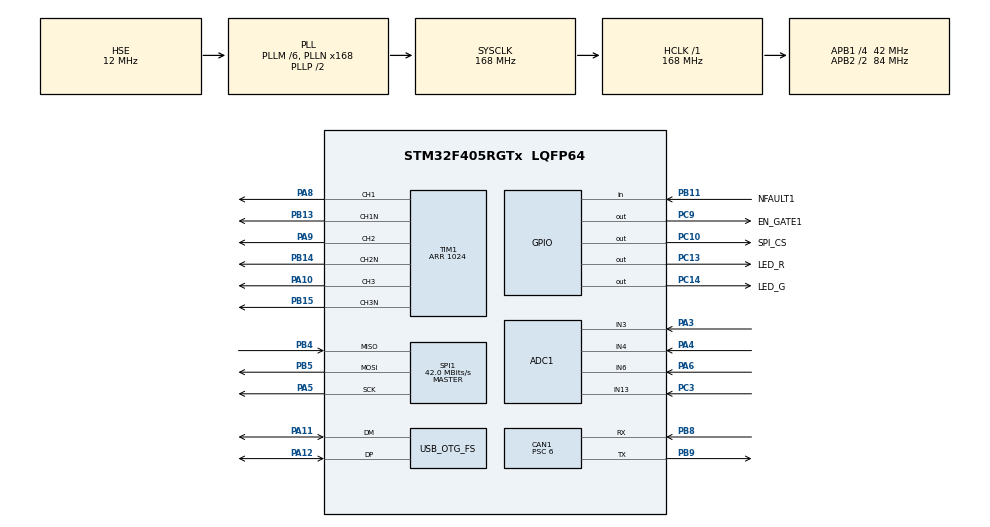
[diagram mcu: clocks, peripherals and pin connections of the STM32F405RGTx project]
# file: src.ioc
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ADC1.Channel-0\#ChannelRegularConversion=ADC_CHANNEL_13
ADC1.Channel-1\#ChannelInjectedConversion=ADC_CHANNEL_13
ADC1.Channel-2\#ChannelInjectedConversion=ADC_CHANNEL_3
ADC1.Channel-3\#ChannelInjectedConversion=ADC_CHANNEL_4
ADC1.Channel-4\#ChannelInjectedConversion=ADC_CHANNEL_6
ADC1.ExternalTrigInjecConv=ADC_EXTERNALTRIGINJECCONV_T1_CC4
ADC1.ExternalTrigInjecConvEdge=ADC_EXTERNALTRIGINJECCONVEDGE_FALLING
ADC1.InjNumberOfConversion=4
ADC1.InjectedOffset-1\#ChannelInjectedConversion=0
ADC1.InjectedOffset-2\#ChannelInjectedConversion=0
ADC1.InjectedOffset-3\#ChannelInjectedConversion=0
ADC1.InjectedOffset-4\#ChannelInjectedConversion=0
ADC1.InjectedRank-1\#ChannelInjectedConversion=1
ADC1.InjectedRank-2\#ChannelInjectedConversion=2
ADC1.InjectedRank-3\#ChannelInjectedConversion=3
ADC1.InjectedRank-4\#ChannelInjectedConversion=4
ADC1.NbrOfConversionFlag=1
ADC1.Rank-0\#ChannelRegularConversion=1
ADC1.SamplingTime-0\#ChannelRegularConversion=ADC_SAMPLETIME_3CYCLES
ADC1.SamplingTime-1\#ChannelInjectedConversion=ADC_SAMPLETIME_28CYCLES
ADC1.SamplingTime-2\#ChannelInjectedConversion=ADC_SAMPLETIME_28CYCLES
ADC1.SamplingTime-3\#ChannelInjectedConversion=ADC_SAMPLETIME_28CYCLES
ADC1.SamplingTime-4\#ChannelInjectedConversion=ADC_SAMPLETIME_28CYCLES
ADC1.ScanConvMode=ENABLE
ADC1.master=1
CAN1.BS1=CAN_BS1_8TQ
CAN1.BS2=CAN_BS2_5TQ
CAN1.CalculateBaudRate=500000
CAN1.CalculateTimeBit=2000
CAN1.CalculateTimeQuantum=142.85714285714286
CAN1.NART=ENABLE
CAN1.Prescaler=6
CAN1.SJW=CAN_SJW_2TQ
Dma.Request0=SPI1_TX
Dma.Request1=SPI1_RX
Dma.SPI1_RX.1.Direction=DMA_PERIPH_TO_MEMORY
Dma.SPI1_RX.1.FIFOMode=DMA_FIFOMODE_DISABLE
Dma.SPI1_RX.1.Instance=DMA2_Stream0
Dma.SPI1_RX.1.MemDataAlignment=DMA_MDATAALIGN_BYTE
Dma.SPI1_RX.1.MemInc=DMA_MINC_ENABLE
Dma.SPI1_RX.1.Mode=DMA_NORMAL
Dma.SPI1_RX.1.PeriphDataAlignment=DMA_PDATAALIGN_BYTE
Dma.SPI1_RX.1.PeriphInc=DMA_PINC_DISABLE
Dma.SPI1_RX.1.Priority=DMA_PRIORITY_HIGH
Dma.SPI1_TX.0.Direction=DMA_MEMORY_TO_PERIPH
Dma.SPI1_TX.0.FIFOMode=DMA_FIFOMODE_DISABLE
Dma.SPI1_TX.0.Instance=DMA2_Stream3
Dma.SPI1_TX.0.MemDataAlignment=DMA_MDATAALIGN_BYTE
Dma.SPI1_TX.0.MemInc=DMA_MINC_ENABLE
Dma.SPI1_TX.0.Mode=DMA_NORMAL
Dma.SPI1_TX.0.PeriphDataAlignment=DMA_PDATAALIGN_BYTE
Dma.SPI1_TX.0.PeriphInc=DMA_PINC_DISABLE
Dma.SPI1_TX.0.Priority=DMA_PRIORITY_HIGH
Mcu.Family=STM32F4
Mcu.Name=STM32F405RGTx
Mcu.Package=LQFP64
NVIC.ADC_IRQn=true\:0\:0\:false\:false\:true\:true\:true\:true
NVIC.CAN1_RX0_IRQn=true\:0\:0\:false\:false\:true\:true\:true\:true
NVIC.CAN1_RX1_IRQn=true\:0\:0\:false\:false\:true\:true\:true\:true
NVIC.DMA2_Stream0_IRQn=true\:0\:0\:false\:false\:true\:false\:true\:true
NVIC.DMA2_Stream3_IRQn=true\:0\:0\:false\:false\:true\:false\:true\:true
NVIC.OTG_FS_IRQn=true\:0\:0\:false\:false\:true\:false\:true\:true
NVIC.PriorityGroup=NVIC_PRIORITYGROUP_4
NVIC.SPI1_IRQn=true\:0\:0\:false\:false\:true\:true\:true\:true
PA10.Signal=S_TIM1_CH3
PA11.Mode=Device_Only
PA11.Signal=USB_OTG_FS_DM
PA12.Mode=Device_Only
PA12.Signal=USB_OTG_FS_DP
PA13.Mode=Serial_Wire
PA13.Signal=SYS_JTMS-SWDIO
PA14.Mode=Serial_Wire
PA14.Signal=SYS_JTCK-SWCLK
PA3.Signal=ADCx_IN3
PA4.Signal=ADCx_IN4
PA5.Mode=Full_Duplex_Master
PA5.Signal=SPI1_SCK
PA6.Signal=ADCx_IN6
PA8.Signal=S_TIM1_CH1
PA9.Signal=S_TIM1_CH2
PB11.GPIO_Label=NFAULT1
PB11.Signal=GPIO_Input
PB13.Mode=PWM Generation1 CH1 CH1N
PB13.Signal=TIM1_CH1N
PB14.Mode=PWM Generation2 CH2 CH2N
PB14.Signal=TIM1_CH2N
PB15.Mode=PWM Generation3 CH3 CH3N
PB15.Signal=TIM1_CH3N
PB4.Mode=Full_Duplex_Master
PB4.Signal=SPI1_MISO
PB5.Mode=Full_Duplex_Master
PB5.Signal=SPI1_MOSI
PB8.GPIO_PuPd=GPIO_PULLUP
PB8.Mode=CAN_Activate
PB8.Signal=CAN1_RX
PB9.Mode=CAN_Activate
PB9.Signal=CAN1_TX
PC10.GPIO_Label=SPI_CS
PC10.Signal=GPIO_Output
PC13-ANTI_TAMP.GPIO_Label=LED_R
PC13-ANTI_TAMP.Signal=GPIO_Output
PC14-OSC32_IN.GPIO_Label=LED_G
PC14-OSC32_IN.Signal=GPIO_Output
PC3.Signal=ADCx_IN13
PC9.GPIO_Label=EN_GATE1
PC9.Signal=GPIO_Output
PH0-OSC_IN.Mode=HSE-External-Oscillator
PH0-OSC_IN.Signal=RCC_OSC_IN
PH1-OSC_OUT.Mode=HSE-External-Oscillator
PH1-OSC_OUT.Signal=RCC_OSC_OUT
ProjectManager.HeapSize=0x200
ProjectManager.StackSize=0x400
ProjectManager.TargetToolchain=EWARM V8.50
RCC.48MHZClocksFreq_Value=48000000
RCC.AHBFreq_Value=168000000
RCC.APB1CLKDivider=RCC_HCLK_DIV4
RCC.APB1Freq_Value=42000000
RCC.APB1TimFreq_Value=84000000
RCC.APB2CLKDivider=RCC_HCLK_DIV2
RCC.APB2Freq_Value=84000000
RCC.APB2TimFreq_Value=168000000
RCC.CortexFreq_Value=168000000
RCC.HCLKFreq_Value=168000000
RCC.HSE_VALUE=12000000
RCC.HSI_VALUE=16000000
RCC.LSE_VALUE=32768
RCC.PLLM=6
RCC.PLLN=168
RCC.PLLQ=7
RCC.SYSCLKFreq_VALUE=168000000
RCC.SYSCLKSource=RCC_SYSCLKSOURCE_PLLCLK
RCC.VCOOutputFreq_Value=336000000
SH.ADCx_IN13.0=ADC1_IN13,IN13
SH.ADCx_IN3.0=ADC1_IN3,IN3
SH.ADCx_IN4.0=ADC1_IN4,IN4
SH.ADCx_IN6.0=ADC1_IN6,IN6
SH.S_TIM1_CH1.0=TIM1_CH1,PWM Generation1 CH1 CH1N
SH.S_TIM1_CH2.0=TIM1_CH2,PWM Generation2 CH2 CH2N
SH.S_TIM1_CH3.0=TIM1_CH3,PWM Generation3 CH3 CH3N
SPI1.CLKPhase=SPI_PHASE_2EDGE
SPI1.CalculateBaudRate=42.0 MBits/s
SPI1.Direction=SPI_DIRECTION_2LINES
SPI1.Mode=SPI_MODE_MASTER
SPI1.VirtualType=VM_MASTER
TIM1.AutomaticOutput=TIM_AUTOMATICOUTPUT_ENABLE
TIM1.Channel-PWM\ Generation1\ CH1\ CH1N=TIM_CHANNEL_1
TIM1.Channel-PWM\ Generation2\ CH2\ CH2N=TIM_CHANNEL_2
TIM1.Channel-PWM\ Generation3\ CH3\ CH3N=TIM_CHANNEL_3
TIM1.Channel-PWM\ Generation4\ No\ Output=TIM_CHANNEL_4
TIM1.CounterMode=TIM_COUNTERMODE_CENTERALIGNED1
TIM1.DeadTime=25
TIM1.OCFastMode_PWM-PWM\ Generation1\ CH1\ CH1N=TIM_OCFAST_ENABLE
TIM1.OCFastMode_PWM-PWM\ Generation2\ CH2\ CH2N=TIM_OCFAST_ENABLE
TIM1.OCFastMode_PWM-PWM\ Generation3\ CH3\ CH3N=TIM_OCFAST_ENABLE
TIM1.OCFastMode_PWM-PWM\ Generation4\ No\ Output=TIM_OCFAST_ENABLE
TIM1.OffStateIDLEMode=TIM_OSSI_ENABLE
TIM1.OffStateRunMode=TIM_OSSR_ENABLE
TIM1.Period=1024
TIM1.TIM_MasterOutputTrigger=TIM_TRGO_UPDATE
USB_DEVICE.CLASS_NAME_FS=CDC
USB_DEVICE.VirtualMode-CDC_FS=Cdc
USB_DEVICE.VirtualModeFS=Cdc_FS
USB_OTG_FS.VirtualMode=Device_Only
VP_TIM1_VS_ClockSourceINT.Mode=Internal
VP_TIM1_VS_no_output4.Mode=PWM Generation4 No Output
VP_USB_DEVICE_VS_USB_DEVICE_CDC_FS.Mode=CDC_FS
board=custom

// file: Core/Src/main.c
/* USER CODE BEGIN Header */
/**
  ******************************************************************************
  * @file           : main.c
  * @brief          : Main program body
  ******************************************************************************
  * @attention
  *
  * Copyright (c) 2026 STMicroelectronics.
  * All rights reserved.
  *
  * This software is licensed under terms that can be found in the LICENSE file
  * in the root directory of this software component.
  * If no LICENSE file comes with this software, it is provided AS-IS.
  *
  ******************************************************************************
  */
/* USER CODE END Header */
#include "main.h"
#include "usb_device.h"

/* USER CODE BEGIN Includes */
#include "device_config.h"
#include "stm32f405_link.h"
#include "motor.h"
#include "AS5047P.h"
#include "FOC_utils.h"
#include "self_commissioning.h"
#include "storage.h"
#include "sf_motion_usb_com.h"
#include "sf_motion_com.h"
#include "string.h"
/* USER CODE END Includes */

/* USER CODE BEGIN PD */

#define usb_print(fmt, ...)                                                 \
  do {                                                                      \
    snprintf(usb_send_buff, sizeof(usb_send_buff), fmt, ##__VA_ARGS__);     \
    CDC_Transmit_FS((uint8_t *)(usb_send_buff), sizeof(usb_send_buff) - 1); \
  } while (0)

/* USER CODE END PD */

/* USER CODE BEGIN PM */
extern uint8_t CDC_Transmit_FS(uint8_t* Buf, uint16_t Len);
/* USER CODE END PM */

ADC_HandleTypeDef hadc1;

CAN_HandleTypeDef hcan1;

SPI_HandleTypeDef hspi1;
DMA_HandleTypeDef hdma_spi1_tx;
DMA_HandleTypeDef hdma_spi1_rx;

TIM_HandleTypeDef htim1;

/* USER CODE BEGIN PV */

AS5047P_t hencd1;
uint32_t adc_buff[4];
foc_t hfoc1;
self_commissioning_t hsc1;
storage_t hstorage1;

sfm_usb_com_t hsfm_usb_com;
sfm_com_t husb_com;
sfm_com_t hcan_com;

char usb_send_buff[64];
uint8_t can_send_buff[64];
uint8_t can_recv_buff[64];

/* USER CODE END PV */

void SystemClock_Config(void);
static void MX_GPIO_Init(void);
static void MX_DMA_Init(void);
static void MX_TIM1_Init(void);
static void MX_ADC1_Init(void);
static void MX_SPI1_Init(void);
static void MX_CAN1_Init(void);

/* USER CODE BEGIN 0 */

/**************************************************************************** */
// implementation

void motor1_inverter_enable(void) {
  EN_GATE1_GPIO_Port->BSRR = EN_GATE1_Pin;
  link_enable_pwm(&htim1);
  link_enable_adc(&hadc1);
}

void motor1_inverter_disable(void) {
  EN_GATE1_GPIO_Port->BSRR = EN_GATE1_Pin<<16;
  link_disable_pwm(&htim1);
  link_disable_adc(&hadc1);
}

uint32_t motor1_get_pwm_res(void) {
  return link_get_max_pwm(&htim1);
}

float motor1_as5047p_get_mech_deg(void) {
  return AS5047P_get_degree(&hencd1);
}

float motor1_as5047p_get_continuous_mech_deg(void) {
  return AS5047P_get_continuous_degree(&hencd1);
}

float motor1_as5047p_get_rpm(void) {
  return AS5047P_get_rpm(&hencd1);
}

int motor1_as5047p_spi_transmit(uint8_t *tx, uint8_t *rx, uint16_t len) {
  if (HAL_SPI_TransmitReceive_DMA(&hspi1, tx, rx, len) == HAL_OK) return 0;
  return -1;
}

void motor1_as5047p_spi_cs(_Bool cs_state) {
  if (cs_state) SPI_CS_GPIO_Port->BSRR = SPI_CS_Pin;
  else SPI_CS_GPIO_Port->BSRR = SPI_CS_Pin<<16;
}

int write_flash(void *data, uint32_t len) {
  return link_write_flash(data, len);
}

int read_flash(void *data, uint32_t len) {
  memcpy(data, (void*)FLASH_SECTOR_ADDR, len);
  return 0;
}

int usb_send_data(uint8_t *data, uint16_t len) {
  if (CDC_Transmit_FS(data, len) != USBD_OK) return -1;
  return 0;
}

int sfm_com_usb_send_data(uint8_t *data, uint16_t len) {
  if (sfm_usb_com_start_send_data(&hsfm_usb_com, data, len) == 0) return 0;
  return -1;
}

int sfm_com_usb_recv_data(uint8_t *data, uint16_t len) {
  (void)data;
  (void)len;
  return 0;
}

int can_recv_data(uint8_t *data, uint16_t len) {
  (void)data;
  (void)len;
  return 0;
}

int can_send_data(uint8_t *data, uint16_t len) {
  uint32_t can_std_id = (data[0] << 8) | data[1];
  return link_can_send_data(can_std_id, data + 2, len);
}

/**************************************************************************** */

static void init_motor(void) {
  // motor pwm
  motor_init_pwm(&hfoc1.motor, &TIM1->CCR1, &TIM1->CCR2, &TIM1->CCR3);
  // current sense
  motor_init_adc_current_sense(&hfoc1.motor, &adc_buff[0], &adc_buff[1], &adc_buff[2]);
  // power voltage sense
  motor_init_adc_power_voltage_sense(&hfoc1.motor, &adc_buff[3]);
  motor_init_lpf_power_voltage_sense(&hfoc1.motor, hstorage1.memory.voltage_sens.filter_fc, BLDC_PWM_FREQ);
  // current sense amplifier calibration enable (for internal CSA only)
  CSA_CAL1_GPIO_Port->BSRR = CSA_CAL1_Pin << 16;
}

static void init_encoder(void) {
  AS5047P_spi_config(&hencd1, motor1_as5047p_spi_transmit, motor1_as5047p_spi_cs);
  AS5047P_init(&hencd1,
              hstorage1.memory.encoder_config.is_dir_inverted? SENSOR_DIR_REVERSE : SENSOR_DIR_NORMAL,
              hstorage1.memory.encoder_config.scale);
  AS5047P_set_pll_filter(&hencd1,
                        hstorage1.memory.encoder_config.pll_filt_bandwidth,
                        hstorage1.memory.encoder_config.pll_filt_damping_ratio,
                        FOC_TS);
}

static void init_foc(void) {
#if USB_TO_CAN
  link_can_init(USB_TO_CAN_DEVICE_ID);
  sfm_usb_com_init(&hsfm_usb_com, usb_send_data);
  sfm_com_init(&husb_com, sfm_com_usb_recv_data, sfm_com_usb_send_data, HAL_GetTick, &hfoc1, &hstorage1, &hsc1);
  sfm_com_init(&hcan_com, can_recv_data, can_send_data, HAL_GetTick, &hfoc1, &hstorage1, &hsc1);
#else
  storage_init(&hstorage1, write_flash, read_flash);
  storage_read_config(&hstorage1);
  storage_copy_to_local(&hstorage1, &hfoc1);

  init_trig_lut();
  link_set_pwm_freq(&htim1, BLDC_PWM_FREQ);
  init_motor();
  init_encoder();
  sc_init(&hsc1, &hfoc1);

  foc_inverter_init(&hfoc1, motor1_inverter_enable, motor1_inverter_disable, motor1_get_pwm_res);
  foc_feedback_sensor_init(&hfoc1,
                          motor1_as5047p_get_mech_deg,
                          motor1_as5047p_get_continuous_mech_deg,
                          motor1_as5047p_get_rpm,
                          hstorage1.memory.encoder_config.error_comp_deg);

  link_can_init(hfoc1.motor.device_id);
  sfm_usb_com_init(&hsfm_usb_com, usb_send_data);
  sfm_com_init(&husb_com,
              sfm_com_usb_recv_data,
              sfm_com_usb_send_data,
              HAL_GetTick,
              link_system_reset,
              &hfoc1, &hstorage1, &hsc1);
  sfm_com_init(&hcan_com,
              can_recv_data,
              can_send_data,
              HAL_GetTick,
              link_system_reset,
              &hfoc1, &hstorage1, &hsc1);

  // Id PI parameter
  pid_reset(&hfoc1.id_ctrl);
  pid_set_ts(&hfoc1.id_ctrl, FOC_TS);
  // Id PI parameter
  pid_reset(&hfoc1.iq_ctrl);
  pid_set_ts(&hfoc1.iq_ctrl, FOC_TS);
  // Speed PID parameter
  pid_reset(&hfoc1.speed_ctrl);
  pid_set_ts(&hfoc1.speed_ctrl, SPEED_TS);
  // Position PID parameter
  pid_reset(&hfoc1.pos_ctrl);
  pid_set_ts(&hfoc1.pos_ctrl, POSITION_TS);
  pid_set_max_d(&hfoc1.pos_ctrl, 100.0f);
  // field weakening
  pid_reset(&hfoc1.fw_ctrl);
  pid_set_ts(&hfoc1.fw_ctrl, FOC_TS);

  // foc_set_mode(&hfoc1, FOC_MODE_SENSORED);
  foc_sensorless_init(&hfoc1, BLDC_PWM_FREQ);

  HAL_Delay(50);
  foc_enable(&hfoc1);
#endif
}

static void indicator_update(void) {
  static uint32_t heartbeat_tick = 0;
  if (HAL_GetTick() - heartbeat_tick >= 500) {
    heartbeat_tick = HAL_GetTick();
    HAL_GPIO_TogglePin(LED_G_GPIO_Port, LED_G_Pin);
  }
  if (HAL_GPIO_ReadPin(NFAULT1_GPIO_Port, NFAULT1_Pin)) {
    LED_R_GPIO_Port->BSRR = LED_R_Pin<<16;
  }
  else {
    LED_R_GPIO_Port->BSRR = LED_R_Pin;
  }
}

static void self_commissioning_update(void) {
  if (sc_is_measure_done(&hsc1)) {
    switch(sc_get_seq(&hsc1)) {
      case SC_SEQUENCE_START_MEASURE_RS:
        foc_set_motor_Rs(&hfoc1, sc_get_Rs(&hsc1));
        break;
      case SC_SEQUENCE_START_MEASURE_LD:
        foc_set_motor_Ld(&hfoc1, sc_get_Ld(&hsc1));
        break;
      case SC_SEQUENCE_START_MEASURE_LQ:
        foc_set_motor_Lq(&hfoc1, sc_get_Lq(&hsc1));
        break;
      case SC_SEQUENCE_START_CALIBRATE_ABS_ENCODER:
        break;
      case SC_SEQUENCE_START_CALC_POLE_PAIRS:
        break;
      default:
        break;
    }
    sfm_com_send_event(&husb_com, SFM_EVENT_SELFCOM_DONE);
    sfm_com_send_event(&hcan_com, SFM_EVENT_SELFCOM_DONE);
  }
}

void usb_to_can_update(void) {
  if (husb_com.incomming_data_flag) {
    husb_com.incomming_data_flag = 0;
    hcan_com.send_data(husb_com.data_rx, husb_com.data_rx_len);
  }
  if (hcan_com.incomming_data_flag) {
    hcan_com.incomming_data_flag = 0;
    husb_com.send_data(hcan_com.data_rx, hcan_com.data_rx_len);
  }
}

/**************************************************************************** */

void HAL_SPI_TxRxCpltCallback(SPI_HandleTypeDef *hspi) {
	if (hspi->Instance == SPI1) {
    AS5047P_set_spi_transfer_done(&hencd1);
	}
}

void HAL_ADCEx_InjectedConvCpltCallback(ADC_HandleTypeDef* hadc) {
	if (hadc->Instance == ADC1) {
    adc_buff[0] = ADC1->JDR1; // current sense A
    adc_buff[1] = ADC1->JDR2; // current sense B
    adc_buff[2] = ADC1->JDR3; // current sense C
    adc_buff[3] = ADC1->JDR4; // power voltage sense
    motor_calculate_power_voltage(&hfoc1.motor);
    motor_get_power_voltage(&hfoc1.motor, &hfoc1.v_bus);
    AS5047P_pll_filter_update(&hencd1);
    sc_update(&hsc1, FOC_TS);
    foc_update(&hfoc1, FOC_TS);
  }
}

// CAN RX FIFO 0 Callback
void HAL_CAN_RxFifo0MsgPendingCallback(CAN_HandleTypeDef *hcan){
  uint32_t id;
  if (link_can_recv_data(&id, hcan_com.data_rx, &hcan_com.data_rx_len) == 0) {
    hcan_com.incomming_data_flag = 1;
  }
}

/**************************************************************************** */

/* USER CODE END 0 */

int main(void)
{

  /* MCU Configuration--------------------------------------------------------*/

  /* Reset of all peripherals, Initializes the Flash interface and the Systick. */
  HAL_Init();

  /* Configure the system clock */
  SystemClock_Config();

  /* Initialize all configured peripherals */
  MX_GPIO_Init();
  MX_DMA_Init();
  MX_USB_DEVICE_Init();
  MX_TIM1_Init();
  MX_ADC1_Init();
  MX_SPI1_Init();
  MX_CAN1_Init();
  /* USER CODE BEGIN 2 */

#if (__FPU_PRESENT == 1) && (__FPU_USED == 1)
  printf("FPU aktif!\n");
#else
  printf("FPU tidak aktif!\n");
#endif

  init_foc();

  /* USER CODE END 2 */

  /* Infinite loop */
  /* USER CODE BEGIN WHILE */
  while (1)
  {
    indicator_update();
#if USB_TO_CAN
    usb_to_can_update();
#else
    AS5047P_update(&hencd1);
    sfm_com_update(&husb_com);
    sfm_com_update(&hcan_com);
    self_commissioning_update();
#endif
    /* USER CODE END WHILE */

  }
}

void SystemClock_Config(void)
{
  RCC_OscInitTypeDef RCC_OscInitStruct = {0};
  RCC_ClkInitTypeDef RCC_ClkInitStruct = {0};

  /** Configure the main internal regulator output voltage
  */
  __HAL_RCC_PWR_CLK_ENABLE();
  __HAL_PWR_VOLTAGESCALING_CONFIG(PWR_REGULATOR_VOLTAGE_SCALE1);

  /** Initializes the RCC Oscillators according to the specified parameters
  * in the RCC_OscInitTypeDef structure.
  */
  RCC_OscInitStruct.OscillatorType = RCC_OSCILLATORTYPE_HSE;
  RCC_OscInitStruct.HSEState = RCC_HSE_ON;
  RCC_OscInitStruct.PLL.PLLState = RCC_PLL_ON;
  RCC_OscInitStruct.PLL.PLLSource = RCC_PLLSOURCE_HSE;
  RCC_OscInitStruct.PLL.PLLM = 6;
  RCC_OscInitStruct.PLL.PLLN = 168;
  RCC_OscInitStruct.PLL.PLLP = RCC_PLLP_DIV2;
  RCC_OscInitStruct.PLL.PLLQ = 7;
  if (HAL_RCC_OscConfig(&RCC_OscInitStruct) != HAL_OK)
  {
    Error_Handler();
  }

  /** Initializes the CPU, AHB and APB buses clocks
  */
  RCC_ClkInitStruct.ClockType = RCC_CLOCKTYPE_HCLK|RCC_CLOCKTYPE_SYSCLK
                              |RCC_CLOCKTYPE_PCLK1|RCC_CLOCKTYPE_PCLK2;
  RCC_ClkInitStruct.SYSCLKSource = RCC_SYSCLKSOURCE_PLLCLK;
  RCC_ClkInitStruct.AHBCLKDivider = RCC_SYSCLK_DIV1;
  RCC_ClkInitStruct.APB1CLKDivider = RCC_HCLK_DIV4;
  RCC_ClkInitStruct.APB2CLKDivider = RCC_HCLK_DIV2;

  if (HAL_RCC_ClockConfig(&RCC_ClkInitStruct, FLASH_LATENCY_5) != HAL_OK)
  {
    Error_Handler();
  }
}

static void MX_ADC1_Init(void)
{

  ADC_ChannelConfTypeDef sConfig = {0};
  ADC_InjectionConfTypeDef sConfigInjected = {0};

  /** Configure the global features of the ADC (Clock, Resolution, Data Alignment and number of conversion)
  */
  hadc1.Instance = ADC1;
  hadc1.Init.ClockPrescaler = ADC_CLOCK_SYNC_PCLK_DIV4;
  hadc1.Init.Resolution = ADC_RESOLUTION_12B;
  hadc1.Init.ScanConvMode = ENABLE;
  hadc1.Init.ContinuousConvMode = DISABLE;
  hadc1.Init.DiscontinuousConvMode = DISABLE;
  hadc1.Init.ExternalTrigConvEdge = ADC_EXTERNALTRIGCONVEDGE_NONE;
  hadc1.Init.ExternalTrigConv = ADC_SOFTWARE_START;
  hadc1.Init.DataAlign = ADC_DATAALIGN_RIGHT;
  hadc1.Init.NbrOfConversion = 1;
  hadc1.Init.DMAContinuousRequests = DISABLE;
  hadc1.Init.EOCSelection = ADC_EOC_SINGLE_CONV;
  if (HAL_ADC_Init(&hadc1) != HAL_OK)
  {
    Error_Handler();
  }

  /** Configure for the selected ADC regular channel its corresponding rank in the sequencer and its sample time.
  */
  sConfig.Channel = ADC_CHANNEL_13;
  sConfig.Rank = 1;
  sConfig.SamplingTime = ADC_SAMPLETIME_3CYCLES;
  if (HAL_ADC_ConfigChannel(&hadc1, &sConfig) != HAL_OK)
  {
    Error_Handler();
  }

  /** Configures for the selected ADC injected channel its corresponding rank in the sequencer and its sample time
  */
  sConfigInjected.InjectedChannel = ADC_CHANNEL_13;
  sConfigInjected.InjectedRank = 1;
  sConfigInjected.InjectedNbrOfConversion = 4;
  sConfigInjected.InjectedSamplingTime = ADC_SAMPLETIME_28CYCLES;
  sConfigInjected.ExternalTrigInjecConvEdge = ADC_EXTERNALTRIGINJECCONVEDGE_FALLING;
  sConfigInjected.ExternalTrigInjecConv = ADC_EXTERNALTRIGINJECCONV_T1_CC4;
  sConfigInjected.AutoInjectedConv = DISABLE;
  sConfigInjected.InjectedDiscontinuousConvMode = DISABLE;
  sConfigInjected.InjectedOffset = 0;
  if (HAL_ADCEx_InjectedConfigChannel(&hadc1, &sConfigInjected) != HAL_OK)
  {
    Error_Handler();
  }

  /** Configures for the selected ADC injected channel its corresponding rank in the sequencer and its sample time
  */
  sConfigInjected.InjectedChannel = ADC_CHANNEL_3;
  sConfigInjected.InjectedRank = 2;
  if (HAL_ADCEx_InjectedConfigChannel(&hadc1, &sConfigInjected) != HAL_OK)
  {
    Error_Handler();
  }

  /** Configures for the selected ADC injected channel its corresponding rank in the sequencer and its sample time
  */
  sConfigInjected.InjectedChannel = ADC_CHANNEL_4;
  sConfigInjected.InjectedRank = 3;
  if (HAL_ADCEx_InjectedConfigChannel(&hadc1, &sConfigInjected) != HAL_OK)
  {
    Error_Handler();
  }

  /** Configures for the selected ADC injected channel its corresponding rank in the sequencer and its sample time
  */
  sConfigInjected.InjectedChannel = ADC_CHANNEL_6;
  sConfigInjected.InjectedRank = 4;
  if (HAL_ADCEx_InjectedConfigChannel(&hadc1, &sConfigInjected) != HAL_OK)
  {
    Error_Handler();
  }

}

static void MX_CAN1_Init(void)
{

  hcan1.Instance = CAN1;
  hcan1.Init.Prescaler = 6;
  hcan1.Init.Mode = CAN_MODE_NORMAL;
  hcan1.Init.SyncJumpWidth = CAN_SJW_2TQ;
  hcan1.Init.TimeSeg1 = CAN_BS1_8TQ;
  hcan1.Init.TimeSeg2 = CAN_BS2_5TQ;
  hcan1.Init.TimeTriggeredMode = DISABLE;
  hcan1.Init.AutoBusOff = DISABLE;
  hcan1.Init.AutoWakeUp = DISABLE;
  hcan1.Init.AutoRetransmission = ENABLE;
  hcan1.Init.ReceiveFifoLocked = DISABLE;
  hcan1.Init.TransmitFifoPriority = DISABLE;
  if (HAL_CAN_Init(&hcan1) != HAL_OK)
  {
    Error_Handler();
  }

}

static void MX_SPI1_Init(void)
{

  /* SPI1 parameter configuration*/
  hspi1.Instance = SPI1;
  hspi1.Init.Mode = SPI_MODE_MASTER;
  hspi1.Init.Direction = SPI_DIRECTION_2LINES;
  hspi1.Init.DataSize = SPI_DATASIZE_8BIT;
  hspi1.Init.CLKPolarity = SPI_POLARITY_LOW;
  hspi1.Init.CLKPhase = SPI_PHASE_2EDGE;
  hspi1.Init.NSS = SPI_NSS_SOFT;
  hspi1.Init.BaudRatePrescaler = SPI_BAUDRATEPRESCALER_4;
  hspi1.Init.FirstBit = SPI_FIRSTBIT_MSB;
  hspi1.Init.TIMode = SPI_TIMODE_DISABLE;
  hspi1.Init.CRCCalculation = SPI_CRCCALCULATION_DISABLE;
  hspi1.Init.CRCPolynomial = 10;
  if (HAL_SPI_Init(&hspi1) != HAL_OK)
  {
    Error_Handler();
  }

}

static void MX_TIM1_Init(void)
{

  TIM_ClockConfigTypeDef sClockSourceConfig = {0};
  TIM_MasterConfigTypeDef sMasterConfig = {0};
  TIM_OC_InitTypeDef sConfigOC = {0};
  TIM_BreakDeadTimeConfigTypeDef sBreakDeadTimeConfig = {0};

  htim1.Instance = TIM1;
  htim1.Init.Prescaler = 0;
  htim1.Init.CounterMode = TIM_COUNTERMODE_CENTERALIGNED1;
  htim1.Init.Period = 1024;
  htim1.Init.ClockDivision = TIM_CLOCKDIVISION_DIV1;
  htim1.Init.RepetitionCounter = 0;
  htim1.Init.AutoReloadPreload = TIM_AUTORELOAD_PRELOAD_DISABLE;
  if (HAL_TIM_Base_Init(&htim1) != HAL_OK)
  {
    Error_Handler();
  }
  sClockSourceConfig.ClockSource = TIM_CLOCKSOURCE_INTERNAL;
  if (HAL_TIM_ConfigClockSource(&htim1, &sClockSourceConfig) != HAL_OK)
  {
    Error_Handler();
  }
  if (HAL_TIM_PWM_Init(&htim1) != HAL_OK)
  {
    Error_Handler();
  }
  sMasterConfig.MasterOutputTrigger = TIM_TRGO_UPDATE;
  sMasterConfig.MasterSlaveMode = TIM_MASTERSLAVEMODE_DISABLE;
  if (HAL_TIMEx_MasterConfigSynchronization(&htim1, &sMasterConfig) != HAL_OK)
  {
    Error_Handler();
  }
  sConfigOC.OCMode = TIM_OCMODE_PWM1;
  sConfigOC.Pulse = 0;
  sConfigOC.OCPolarity = TIM_OCPOLARITY_HIGH;
  sConfigOC.OCNPolarity = TIM_OCNPOLARITY_HIGH;
  sConfigOC.OCFastMode = TIM_OCFAST_ENABLE;
  sConfigOC.OCIdleState = TIM_OCIDLESTATE_RESET;
  sConfigOC.OCNIdleState = TIM_OCNIDLESTATE_RESET;
  if (HAL_TIM_PWM_ConfigChannel(&htim1, &sConfigOC, TIM_CHANNEL_1) != HAL_OK)
  {
    Error_Handler();
  }
  if (HAL_TIM_PWM_ConfigChannel(&htim1, &sConfigOC, TIM_CHANNEL_2) != HAL_OK)
  {
    Error_Handler();
  }
  if (HAL_TIM_PWM_ConfigChannel(&htim1, &sConfigOC, TIM_CHANNEL_3) != HAL_OK)
  {
    Error_Handler();
  }
  if (HAL_TIM_PWM_ConfigChannel(&htim1, &sConfigOC, TIM_CHANNEL_4) != HAL_OK)
  {
    Error_Handler();
  }
  sBreakDeadTimeConfig.OffStateRunMode = TIM_OSSR_ENABLE;
  sBreakDeadTimeConfig.OffStateIDLEMode = TIM_OSSI_ENABLE;
  sBreakDeadTimeConfig.LockLevel = TIM_LOCKLEVEL_OFF;
  sBreakDeadTimeConfig.DeadTime = 25;
  sBreakDeadTimeConfig.BreakState = TIM_BREAK_DISABLE;
  sBreakDeadTimeConfig.BreakPolarity = TIM_BREAKPOLARITY_HIGH;
  sBreakDeadTimeConfig.AutomaticOutput = TIM_AUTOMATICOUTPUT_ENABLE;
  if (HAL_TIMEx_ConfigBreakDeadTime(&htim1, &sBreakDeadTimeConfig) != HAL_OK)
  {
    Error_Handler();
  }
  HAL_TIM_MspPostInit(&htim1);

}

static void MX_DMA_Init(void)
{

  /* DMA controller clock enable */
  __HAL_RCC_DMA2_CLK_ENABLE();

  /* DMA interrupt init */
  /* DMA2_Stream0_IRQn interrupt configuration */
  HAL_NVIC_SetPriority(DMA2_Stream0_IRQn, 0, 0);
  HAL_NVIC_EnableIRQ(DMA2_Stream0_IRQn);
  /* DMA2_Stream3_IRQn interrupt configuration */
  HAL_NVIC_SetPriority(DMA2_Stream3_IRQn, 0, 0);
  HAL_NVIC_EnableIRQ(DMA2_Stream3_IRQn);

}

static void MX_GPIO_Init(void)
{
  GPIO_InitTypeDef GPIO_InitStruct = {0};

  /* GPIO Ports Clock Enable */
  __HAL_RCC_GPIOC_CLK_ENABLE();
  __HAL_RCC_GPIOH_CLK_ENABLE();
  __HAL_RCC_GPIOA_CLK_ENABLE();
  __HAL_RCC_GPIOB_CLK_ENABLE();

  /*Configure GPIO pin Output Level */
  HAL_GPIO_WritePin(GPIOC, LED_R_Pin|LED_G_Pin|CSA_CAL1_Pin|EN_GATE1_Pin
                          |SPI_CS_Pin, GPIO_PIN_RESET);

  /*Configure GPIO pins : LED_R_Pin LED_G_Pin CSA_CAL1_Pin EN_GATE1_Pin
                           SPI_CS_Pin */
  GPIO_InitStruct.Pin = LED_R_Pin|LED_G_Pin|CSA_CAL1_Pin|EN_GATE1_Pin
                          |SPI_CS_Pin;
  GPIO_InitStruct.Mode = GPIO_MODE_OUTPUT_PP;
  GPIO_InitStruct.Pull = GPIO_NOPULL;
  GPIO_InitStruct.Speed = GPIO_SPEED_FREQ_LOW;
  HAL_GPIO_Init(GPIOC, &GPIO_InitStruct);

  /*Configure GPIO pin : NFAULT1_Pin */
  GPIO_InitStruct.Pin = NFAULT1_Pin;
  GPIO_InitStruct.Mode = GPIO_MODE_INPUT;
  GPIO_InitStruct.Pull = GPIO_NOPULL;
  HAL_GPIO_Init(NFAULT1_GPIO_Port, &GPIO_InitStruct);

}

void Error_Handler(void)
{
  __disable_irq();
  while (1)
  {
  }
}
